# CC27x0 register map
File version: 1.0
CPU: CM4 r0p4, little endian, no MPU, no FPU, VTOR, 3 interrupt priority bits
Registers are 32-bit, read-write, reset 0x0 unless marked. A register's access mark holds for its fields unless they carry their own. Offsets are from the block's base; [hi:lo] are bit positions; {n}, {i} and the like mark numbered series; 'fields as' and 'values as' point back to an identical list.

## LRFDMDM32 (part 1 of 2)
Base 0x40082400
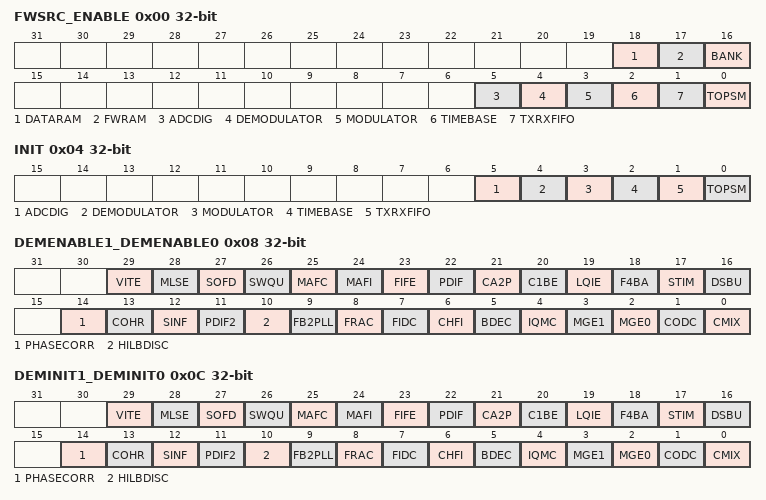
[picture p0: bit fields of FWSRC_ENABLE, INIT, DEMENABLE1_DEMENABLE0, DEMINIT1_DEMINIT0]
0x00 FWSRC_ENABLE — Internal. Only to be used through TI provided API.
  [18] DATARAM — Internal. Only to be used through TI provided API.
    1=S2RRAM (Internal. Only to be used through TI provided API.); 0=MDMRAM (Internal. Only to be used through TI provided API.)
  [17] FWRAM — Internal. Only to be used through TI provided API.
    values as DATARAM
  [16] BANK — Internal. Only to be used through TI provided API.
    1=ONE (Internal. Only to be used through TI provided API.); 0=ZERO (Internal. Only to be used through TI provided API.)
  [5] ADCDIG — Internal. Only to be used through TI provided API.
    1=EN (Internal. Only to be used through TI provided API.); 0=DIS (Internal. Only to be used through TI provided API.)
  [4] DEMODULATOR — Internal. Only to be used through TI provided API.
    values as ADCDIG
  [3] MODULATOR — Internal. Only to be used through TI provided API.
    values as ADCDIG
  [2] TIMEBASE — Internal. Only to be used through TI provided API.
    values as ADCDIG
  [1] TXRXFIFO — Internal. Only to be used through TI provided API.
    values as ADCDIG
  [0] TOPSM — Internal. Only to be used through TI provided API.
    values as ADCDIG
0x04 INIT wo — Internal. Only to be used through TI provided API.
  [all] fields
    1=RESET (Internal. Only to be used through TI provided API.); 0=NO_EFFECT (Internal. Only to be used through TI provided API.)
  [5] ADCDIG — Internal. Only to be used through TI provided API.
  [4] DEMODULATOR — Internal. Only to be used through TI provided API.
  [3] MODULATOR — Internal. Only to be used through TI provided API.
  [2] TIMEBASE — Internal. Only to be used through TI provided API.
  [1] TXRXFIFO — Internal. Only to be used through TI provided API.
  [0] TOPSM — Internal. Only to be used through TI provided API.
0x08 DEMENABLE1_DEMENABLE0 — Internal. Only to be used through TI provided API.
  [29] VITE — Internal. Only to be used through TI provided API.
    values as FWSRC_ENABLE.ADCDIG
  [28] MLSE — Internal. Only to be used through TI provided API.
    values as FWSRC_ENABLE.ADCDIG
  [27] SOFD — Internal. Only to be used through TI provided API.
    values as FWSRC_ENABLE.ADCDIG
  [26] SWQU — Internal. Only to be used through TI provided API.
    values as FWSRC_ENABLE.ADCDIG
  [25] MAFC — Internal. Only to be used through TI provided API.
    values as FWSRC_ENABLE.ADCDIG
  [24] MAFI — Internal. Only to be used through TI provided API.
    values as FWSRC_ENABLE.ADCDIG
  [23] FIFE — Internal. Only to be used through TI provided API.
    values as FWSRC_ENABLE.ADCDIG
  [22] PDIF — Internal. Only to be used through TI provided API.
    values as FWSRC_ENABLE.ADCDIG
  [21] CA2P — Internal. Only to be used through TI provided API.
    values as FWSRC_ENABLE.ADCDIG
  [20] C1BE — Internal. Only to be used through TI provided API.
    values as FWSRC_ENABLE.ADCDIG
  [19] LQIE — Internal. Only to be used through TI provided API.
    values as FWSRC_ENABLE.ADCDIG
  [18] F4BA — Internal. Only to be used through TI provided API.
    values as FWSRC_ENABLE.ADCDIG
  [17] STIM — Internal. Only to be used through TI provided API.
    values as FWSRC_ENABLE.ADCDIG
  [16] DSBU — Internal. Only to be used through TI provided API.
    values as FWSRC_ENABLE.ADCDIG
  [14] PHASECORR — Internal. Only to be used through TI provided API.
  [13] COHR — Internal. Only to be used through TI provided API.
  [12] SINF — Internal. Only to be used through TI provided API.
  [11] PDIF2 — Internal. Only to be used through TI provided API.
  [10] HILBDISC — Internal. Only to be used through TI provided API.
  [9] FB2PLL — Internal. Only to be used through TI provided API.
  [8] FRAC — Internal. Only to be used through TI provided API.
    values as FWSRC_ENABLE.ADCDIG
  [7] FIDC — Internal. Only to be used through TI provided API.
    values as FWSRC_ENABLE.ADCDIG
  [6] CHFI — Internal. Only to be used through TI provided API.
    values as FWSRC_ENABLE.ADCDIG
  [5] BDEC — Internal. Only to be used through TI provided API.
    values as FWSRC_ENABLE.ADCDIG
  [4] IQMC — Internal. Only to be used through TI provided API.
    values as FWSRC_ENABLE.ADCDIG
  [3] MGE1 — Internal. Only to be used through TI provided API.
    values as FWSRC_ENABLE.ADCDIG
  [2] MGE0 — Internal. Only to be used through TI provided API.
    values as FWSRC_ENABLE.ADCDIG
  [1] CODC — Internal. Only to be used through TI provided API.
    values as FWSRC_ENABLE.ADCDIG
  [0] CMIX — Internal. Only to be used through TI provided API.
    values as FWSRC_ENABLE.ADCDIG
0x0C DEMINIT1_DEMINIT0 wo — Internal. Only to be used through TI provided API.
  [29] VITE — Internal. Only to be used through TI provided API.
    values as the fields of INIT
  [28] MLSE — Internal. Only to be used through TI provided API.
    values as the fields of INIT
  [27] SOFD — Internal. Only to be used through TI provided API.
    values as the fields of INIT
  [26] SWQU — Internal. Only to be used through TI provided API.
    values as the fields of INIT
  [25] MAFC — Internal. Only to be used through TI provided API.
    values as the fields of INIT
  [24] MAFI — Internal. Only to be used through TI provided API.
    values as the fields of INIT
  [23] FIFE — Internal. Only to be used through TI provided API.
    values as the fields of INIT
  [22] PDIF — Internal. Only to be used through TI provided API.
    values as the fields of INIT
  [21] CA2P — Internal. Only to be used through TI provided API.
    values as the fields of INIT
  [20] C1BE — Internal. Only to be used through TI provided API.
    values as the fields of INIT
  [19] LQIE — Internal. Only to be used through TI provided API.
    values as the fields of INIT
  [18] F4BA — Internal. Only to be used through TI provided API.
    values as the fields of INIT
  [17] STIM — Internal. Only to be used through TI provided API.
    values as the fields of INIT
  [16] DSBU — Internal. Only to be used through TI provided API.
    values as the fields of INIT
  [14] PHASECORR — Internal. Only to be used through TI provided API.
  [13] COHR — Internal. Only to be used through TI provided API.
  [12] SINF — Internal. Only to be used through TI provided API.
  [11] PDIF2 — Internal. Only to be used through TI provided API.
  [10] HILBDISC — Internal. Only to be used through TI provided API.
  [9] FB2PLL — Internal. Only to be used through TI provided API.
  [8] FRAC — Internal. Only to be used through TI provided API.
    values as the fields of INIT
  [7] FIDC — Internal. Only to be used through TI provided API.
    values as the fields of INIT
  [6] CHFI — Internal. Only to be used through TI provided API.
    values as the fields of INIT
  [5] BDEC — Internal. Only to be used through TI provided API.
    values as the fields of INIT
  [4] IQMC — Internal. Only to be used through TI provided API.
    values as the fields of INIT
  [3] MGE1 — Internal. Only to be used through TI provided API.
    values as the fields of INIT
  [2] MGE0 — Internal. Only to be used through TI provided API.
    values as the fields of INIT
  [1] CODC — Internal. Only to be used through TI provided API.
    values as the fields of INIT
  [0] CMIX — Internal. Only to be used through TI provided API.
    values as the fields of INIT
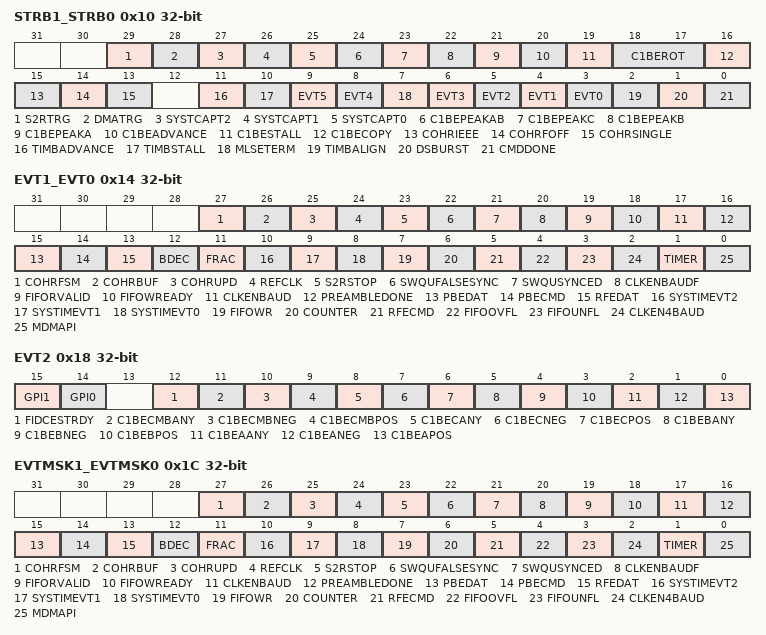
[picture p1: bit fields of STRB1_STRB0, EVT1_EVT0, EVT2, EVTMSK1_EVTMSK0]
0x10 STRB1_STRB0 wo — Internal. Only to be used through TI provided API.
  [29] S2RTRG — Internal. Only to be used through TI provided API.
    values as FWSRC_ENABLE.BANK
  [28] DMATRG — Internal. Only to be used through TI provided API.
    values as FWSRC_ENABLE.BANK
  [27] SYSTCAPT2 — Internal. Only to be used through TI provided API.
    values as FWSRC_ENABLE.BANK
  [26] SYSTCAPT1 — Internal. Only to be used through TI provided API.
    values as FWSRC_ENABLE.BANK
  [25] SYSTCAPT0 — Internal. Only to be used through TI provided API.
    values as FWSRC_ENABLE.BANK
  [24] C1BEPEAKAB — Internal. Only to be used through TI provided API.
    values as FWSRC_ENABLE.BANK
  [23] C1BEPEAKC — Internal. Only to be used through TI provided API.
    values as FWSRC_ENABLE.BANK
  [22] C1BEPEAKB — Internal. Only to be used through TI provided API.
    values as FWSRC_ENABLE.BANK
  [21] C1BEPEAKA — Internal. Only to be used through TI provided API.
    values as FWSRC_ENABLE.BANK
  [20] C1BEADVANCE — Internal. Only to be used through TI provided API.
    values as FWSRC_ENABLE.BANK
  [19] C1BESTALL — Internal. Only to be used through TI provided API.
    values as FWSRC_ENABLE.BANK
  [18:17] C1BEROT — Internal. Only to be used through TI provided API.
    3=ROT16R (Internal. Only to be used through TI provided API.); 2=ROT1L (Internal. Only to be used through TI provided API.); 1=ROT1R (Internal. Only to be used through TI provided API.); 0=ROT0 (Internal. Only to be used through TI provided API.)
  [16] C1BECOPY — Internal. Only to be used through TI provided API.
    values as FWSRC_ENABLE.BANK
  [15] COHRIEEE — Internal. Only to be used through TI provided API.
  [14] COHRFOFF — Internal. Only to be used through TI provided API.
  [13] COHRSINGLE — Internal. Only to be used through TI provided API.
  [11] TIMBADVANCE — Internal. Only to be used through TI provided API.
    1=ON (Internal. Only to be used through TI provided API.); 0=NO_EFFECT (Internal. Only to be used through TI provided API.)
  [10] TIMBSTALL — Internal. Only to be used through TI provided API.
    values as TIMBADVANCE
  [9] EVT5 — Internal. Only to be used through TI provided API.
    values as FWSRC_ENABLE.BANK
  [8] EVT4 — Internal. Only to be used through TI provided API.
    values as FWSRC_ENABLE.BANK
  [7] MLSETERM — Internal. Only to be used through TI provided API.
    1=ON (Internal. Only to be used through TI provided API.); 0=OFF (Internal. Only to be used through TI provided API.)
  [n+3] EVT{n} (n=0..3) — Internal. Only to be used through TI provided API.
    values as FWSRC_ENABLE.BANK
  [2] TIMBALIGN — Internal. Only to be used through TI provided API.
    values as TIMBADVANCE
  [1] DSBURST — Internal. Only to be used through TI provided API.
    1=RESTART (Internal. Only to be used through TI provided API.); 0=NO_EFFECT (Internal. Only to be used through TI provided API.)
  [0] CMDDONE — Internal. Only to be used through TI provided API.
    1=YES (Internal. Only to be used through TI provided API.); 0=NO (Internal. Only to be used through TI provided API.)
0x14 EVT1_EVT0 ro — Internal. Only to be used through TI provided API.
  [27] COHRFSM — Internal. Only to be used through TI provided API.
  [26] COHRBUF — Internal. Only to be used through TI provided API.
  [25] COHRUPD — Internal. Only to be used through TI provided API.
  [24] REFCLK — Internal. Only to be used through TI provided API.
    values as FWSRC_ENABLE.BANK
  [23] S2RSTOP — Internal. Only to be used through TI provided API.
    values as FWSRC_ENABLE.BANK
  [22] SWQUFALSESYNC — Internal. Only to be used through TI provided API.
    values as FWSRC_ENABLE.BANK
  [21] SWQUSYNCED — Internal. Only to be used through TI provided API.
    values as FWSRC_ENABLE.BANK
  [20] CLKENBAUDF — Internal. Only to be used through TI provided API.
    values as FWSRC_ENABLE.BANK
  [19] FIFORVALID — Internal. Only to be used through TI provided API.
    values as FWSRC_ENABLE.BANK
  [18] FIFOWREADY — Internal. Only to be used through TI provided API.
    values as FWSRC_ENABLE.BANK
  [17] CLKENBAUD — Internal. Only to be used through TI provided API.
    values as FWSRC_ENABLE.BANK
  [16] PREAMBLEDONE — Internal. Only to be used through TI provided API.
    values as FWSRC_ENABLE.BANK
  [15] PBEDAT — Internal. Only to be used through TI provided API.
    values as FWSRC_ENABLE.BANK
  [14] PBECMD — Internal. Only to be used through TI provided API.
    values as FWSRC_ENABLE.BANK
  [13] RFEDAT — Internal. Only to be used through TI provided API.
    values as FWSRC_ENABLE.BANK
  [12] BDEC — Internal. Only to be used through TI provided API.
    values as FWSRC_ENABLE.BANK
  [11] FRAC — Internal. Only to be used through TI provided API.
    values as FWSRC_ENABLE.BANK
  [10] SYSTIMEVT2 — Internal. Only to be used through TI provided API.
    values as FWSRC_ENABLE.BANK
  [9] SYSTIMEVT1 — Internal. Only to be used through TI provided API.
    values as FWSRC_ENABLE.BANK
  [8] SYSTIMEVT0 — Internal. Only to be used through TI provided API.
    values as FWSRC_ENABLE.BANK
  [7] FIFOWR — Internal. Only to be used through TI provided API.
    values as FWSRC_ENABLE.BANK
  [6] COUNTER — Internal. Only to be used through TI provided API.
    values as FWSRC_ENABLE.BANK
  [5] RFECMD — Internal. Only to be used through TI provided API.
    values as FWSRC_ENABLE.BANK
  [4] FIFOOVFL — Internal. Only to be used through TI provided API.
    values as FWSRC_ENABLE.BANK
  [3] FIFOUNFL — Internal. Only to be used through TI provided API.
    values as FWSRC_ENABLE.BANK
  [2] CLKEN4BAUD — Internal. Only to be used through TI provided API.
    values as FWSRC_ENABLE.BANK
  [1] TIMER — Internal. Only to be used through TI provided API.
    values as FWSRC_ENABLE.BANK
  [0] MDMAPI — Internal. Only to be used through TI provided API.
    values as FWSRC_ENABLE.BANK
0x18 EVT2 ro — Internal. Only to be used through TI provided API.
  [all] fields
    values as FWSRC_ENABLE.BANK
  [15] GPI1 — Internal. Only to be used through TI provided API.
  [14] GPI0 — Internal. Only to be used through TI provided API.
  [12] FIDCESTRDY — Internal. Only to be used through TI provided API.
  [11] C1BECMBANY — Internal. Only to be used through TI provided API.
  [10] C1BECMBNEG — Internal. Only to be used through TI provided API.
  [9] C1BECMBPOS — Internal. Only to be used through TI provided API.
  [8] C1BECANY — Internal. Only to be used through TI provided API.
  [7] C1BECNEG — Internal. Only to be used through TI provided API.
  [6] C1BECPOS — Internal. Only to be used through TI provided API.
  [5] C1BEBANY — Internal. Only to be used through TI provided API.
  [4] C1BEBNEG — Internal. Only to be used through TI provided API.
  [3] C1BEBPOS — Internal. Only to be used through TI provided API.
  [2] C1BEAANY — Internal. Only to be used through TI provided API.
  [1] C1BEANEG — Internal. Only to be used through TI provided API.
  [0] C1BEAPOS — Internal. Only to be used through TI provided API.
0x1C EVTMSK1_EVTMSK0 — Internal. Only to be used through TI provided API.
  [27] COHRFSM — Internal. Only to be used through TI provided API.
  [26] COHRBUF — Internal. Only to be used through TI provided API.
  [25] COHRUPD — Internal. Only to be used through TI provided API.
  [24] REFCLK — Internal. Only to be used through TI provided API.
    values as FWSRC_ENABLE.ADCDIG
  [23] S2RSTOP — Internal. Only to be used through TI provided API.
    values as FWSRC_ENABLE.ADCDIG
  [22] SWQUFALSESYNC — Internal. Only to be used through TI provided API.
    values as FWSRC_ENABLE.ADCDIG
  [21] SWQUSYNCED — Internal. Only to be used through TI provided API.
    values as FWSRC_ENABLE.ADCDIG
  [20] CLKENBAUDF — Internal. Only to be used through TI provided API.
    values as FWSRC_ENABLE.ADCDIG
  [19] FIFORVALID — Internal. Only to be used through TI provided API.
    values as FWSRC_ENABLE.ADCDIG
  [18] FIFOWREADY — Internal. Only to be used through TI provided API.
    values as FWSRC_ENABLE.ADCDIG
  [17] CLKENBAUD — Internal. Only to be used through TI provided API.
    values as FWSRC_ENABLE.ADCDIG
  [16] PREAMBLEDONE — Internal. Only to be used through TI provided API.
    values as FWSRC_ENABLE.ADCDIG
  [15] PBEDAT — Internal. Only to be used through TI provided API.
    values as FWSRC_ENABLE.ADCDIG
  [14] PBECMD — Internal. Only to be used through TI provided API.
    values as FWSRC_ENABLE.ADCDIG
  [13] RFEDAT — Internal. Only to be used through TI provided API.
    values as FWSRC_ENABLE.ADCDIG
  [12] BDEC — Internal. Only to be used through TI provided API.
    values as FWSRC_ENABLE.ADCDIG
  [11] FRAC — Internal. Only to be used through TI provided API.
    values as FWSRC_ENABLE.ADCDIG
  [10] SYSTIMEVT2 — Internal. Only to be used through TI provided API.
    values as FWSRC_ENABLE.ADCDIG
  [9] SYSTIMEVT1 — Internal. Only to be used through TI provided API.
    values as FWSRC_ENABLE.ADCDIG
  [8] SYSTIMEVT0 — Internal. Only to be used through TI provided API.
    values as FWSRC_ENABLE.ADCDIG
  [7] FIFOWR — Internal. Only to be used through TI provided API.
    values as FWSRC_ENABLE.ADCDIG
  [6] COUNTER — Internal. Only to be used through TI provided API.
    values as FWSRC_ENABLE.ADCDIG
  [5] RFECMD — Internal. Only to be used through TI provided API.
    values as FWSRC_ENABLE.ADCDIG
  [4] FIFOOVFL — Internal. Only to be used through TI provided API.
    values as FWSRC_ENABLE.ADCDIG
  [3] FIFOUNFL — Internal. Only to be used through TI provided API.
    values as FWSRC_ENABLE.ADCDIG
  [2] CLKEN4BAUD — Internal. Only to be used through TI provided API.
    values as FWSRC_ENABLE.ADCDIG
  [1] TIMER — Internal. Only to be used through TI provided API.
    values as FWSRC_ENABLE.ADCDIG
  [0] MDMAPI — Internal. Only to be used through TI provided API.
    values as FWSRC_ENABLE.ADCDIG
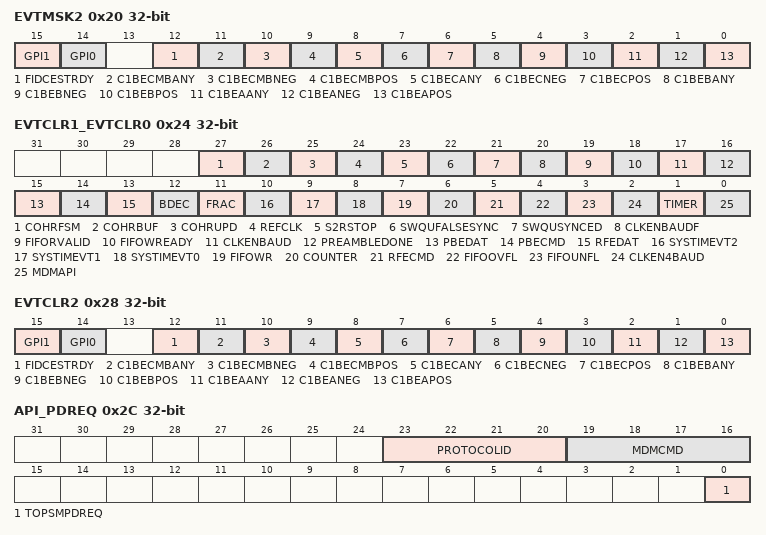
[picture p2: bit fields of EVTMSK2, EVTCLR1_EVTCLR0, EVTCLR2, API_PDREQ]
0x20 EVTMSK2 — Internal. Only to be used through TI provided API.
  [all] fields
    values as FWSRC_ENABLE.ADCDIG
  [15] GPI1 — Internal. Only to be used through TI provided API.
  [14] GPI0 — Internal. Only to be used through TI provided API.
  [12] FIDCESTRDY — Internal. Only to be used through TI provided API.
  [11] C1BECMBANY — Internal. Only to be used through TI provided API.
  [10] C1BECMBNEG — Internal. Only to be used through TI provided API.
  [9] C1BECMBPOS — Internal. Only to be used through TI provided API.
  [8] C1BECANY — Internal. Only to be used through TI provided API.
  [7] C1BECNEG — Internal. Only to be used through TI provided API.
  [6] C1BECPOS — Internal. Only to be used through TI provided API.
  [5] C1BEBANY — Internal. Only to be used through TI provided API.
  [4] C1BEBNEG — Internal. Only to be used through TI provided API.
  [3] C1BEBPOS — Internal. Only to be used through TI provided API.
  [2] C1BEAANY — Internal. Only to be used through TI provided API.
  [1] C1BEANEG — Internal. Only to be used through TI provided API.
  [0] C1BEAPOS — Internal. Only to be used through TI provided API.
0x24 EVTCLR1_EVTCLR0 wo — Internal. Only to be used through TI provided API.
  [27] COHRFSM — Internal. Only to be used through TI provided API.
  [26] COHRBUF — Internal. Only to be used through TI provided API.
  [25] COHRUPD — Internal. Only to be used through TI provided API.
  [24] REFCLK — Internal. Only to be used through TI provided API.
    1=CLEAR (Internal. Only to be used through TI provided API.); 0=RETAIN (Internal. Only to be used through TI provided API.)
  [23] S2RSTOP — Internal. Only to be used through TI provided API.
    values as REFCLK
  [22] SWQUFALSESYNC — Internal. Only to be used through TI provided API.
    values as REFCLK
  [21] SWQUSYNCED — Internal. Only to be used through TI provided API.
    values as REFCLK
  [20] CLKENBAUDF — Internal. Only to be used through TI provided API.
    values as REFCLK
  [19] FIFORVALID — Internal. Only to be used through TI provided API.
    values as REFCLK
  [18] FIFOWREADY — Internal. Only to be used through TI provided API.
    values as REFCLK
  [17] CLKENBAUD — Internal. Only to be used through TI provided API.
    values as REFCLK
  [16] PREAMBLEDONE — Internal. Only to be used through TI provided API.
    values as REFCLK
  [15] PBEDAT — Internal. Only to be used through TI provided API.
    values as REFCLK
  [14] PBECMD — Internal. Only to be used through TI provided API.
    values as REFCLK
  [13] RFEDAT — Internal. Only to be used through TI provided API.
    values as REFCLK
  [12] BDEC — Internal. Only to be used through TI provided API.
    values as REFCLK
  [11] FRAC — Internal. Only to be used through TI provided API.
    values as REFCLK
  [10] SYSTIMEVT2 — Internal. Only to be used through TI provided API.
    values as REFCLK
  [9] SYSTIMEVT1 — Internal. Only to be used through TI provided API.
    values as REFCLK
  [8] SYSTIMEVT0 — Internal. Only to be used through TI provided API.
    values as REFCLK
  [7] FIFOWR — Internal. Only to be used through TI provided API.
    values as REFCLK
  [6] COUNTER — Internal. Only to be used through TI provided API.
    values as REFCLK
  [5] RFECMD — Internal. Only to be used through TI provided API.
    values as REFCLK
  [4] FIFOOVFL — Internal. Only to be used through TI provided API.
    values as REFCLK
  [3] FIFOUNFL — Internal. Only to be used through TI provided API.
    values as REFCLK
  [2] CLKEN4BAUD — Internal. Only to be used through TI provided API.
    values as REFCLK
  [1] TIMER — Internal. Only to be used through TI provided API.
    values as REFCLK
  [0] MDMAPI — Internal. Only to be used through TI provided API.
    values as REFCLK
0x28 EVTCLR2 wo — Internal. Only to be used through TI provided API.
  [all] fields
    values as EVTCLR1_EVTCLR0.REFCLK
  [15] GPI1 — Internal. Only to be used through TI provided API.
  [14] GPI0 — Internal. Only to be used through TI provided API.
  [12] FIDCESTRDY — Internal. Only to be used through TI provided API.
  [11] C1BECMBANY — Internal. Only to be used through TI provided API.
  [10] C1BECMBNEG — Internal. Only to be used through TI provided API.
  [9] C1BECMBPOS — Internal. Only to be used through TI provided API.
  [8] C1BECANY — Internal. Only to be used through TI provided API.
  [7] C1BECNEG — Internal. Only to be used through TI provided API.
  [6] C1BECPOS — Internal. Only to be used through TI provided API.
  [5] C1BEBANY — Internal. Only to be used through TI provided API.
  [4] C1BEBNEG — Internal. Only to be used through TI provided API.
  [3] C1BEBPOS — Internal. Only to be used through TI provided API.
  [2] C1BEAANY — Internal. Only to be used through TI provided API.
  [1] C1BEANEG — Internal. Only to be used through TI provided API.
  [0] C1BEAPOS — Internal. Only to be used through TI provided API.
0x2C API_PDREQ — Internal. Only to be used through TI provided API.
  [23:20] PROTOCOLID ro — Internal. Only to be used through TI provided API.
    15=ALLONES (Internal. Only to be used through TI provided API.); 0=ALLZEROS (Internal. Only to be used through TI provided API.)
  [19:16] MDMCMD ro — Internal. Only to be used through TI provided API.
    values as PROTOCOLID
  [0] TOPSMPDREQ — Internal. Only to be used through TI provided API.
    values as STRB1_STRB0.MLSETERM
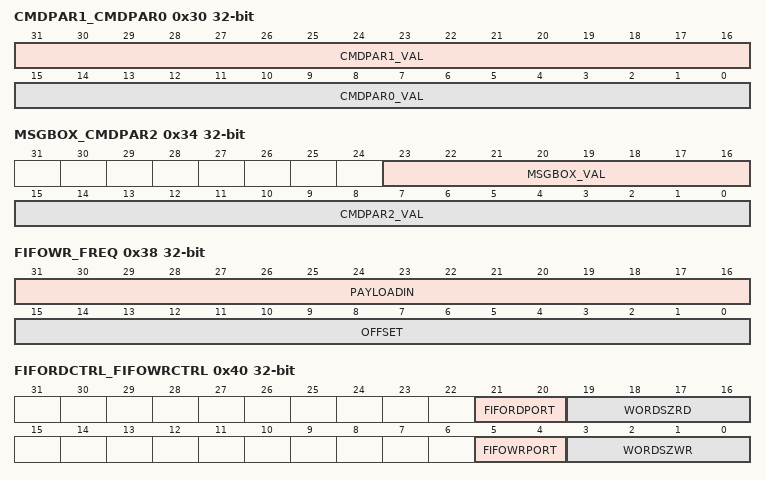
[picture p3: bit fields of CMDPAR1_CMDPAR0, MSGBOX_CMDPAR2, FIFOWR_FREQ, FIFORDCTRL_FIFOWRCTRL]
0x30 CMDPAR1_CMDPAR0 ro — Internal. Only to be used through TI provided API.
  [31:16] CMDPAR1_VAL — Internal. Only to be used through TI provided API.
    0xFFFF=ALLONES (Internal. Only to be used through TI provided API.); 0=ALLZEROS (Internal. Only to be used through TI provided API.)
  [15:0] CMDPAR0_VAL — Internal. Only to be used through TI provided API.
    values as CMDPAR1_VAL
0x34 MSGBOX_CMDPAR2 ro — Internal. Only to be used through TI provided API.
  [23:16] MSGBOX_VAL — Internal. Only to be used through TI provided API.
    255=ALLONES (Internal. Only to be used through TI provided API.); 0=ALLZEROS (Internal. Only to be used through TI provided API.)
  [15:0] CMDPAR2_VAL — Internal. Only to be used through TI provided API.
    values as CMDPAR1_CMDPAR0.CMDPAR1_VAL
0x38 FIFOWR_FREQ — Internal. Only to be used through TI provided API.
  [31:16] PAYLOADIN — Internal. Only to be used through TI provided API.
    values as CMDPAR1_CMDPAR0.CMDPAR1_VAL
  [15:0] OFFSET — Internal. Only to be used through TI provided API.
    values as CMDPAR1_CMDPAR0.CMDPAR1_VAL
0x3C FIFORD ro — Internal. Only to be used through TI provided API.
  [15:0] PAYLOADOUT
    values as CMDPAR1_CMDPAR0.CMDPAR1_VAL
0x40 FIFORDCTRL_FIFOWRCTRL — Internal. Only to be used through TI provided API.
  [21:20] FIFORDPORT — Internal. Only to be used through TI provided API.
    2=PBE (Internal. Only to be used through TI provided API.); 1=MODEM (Internal. Only to be used through TI provided API.); 0=MDMFIFORD (Internal. Only to be used through TI provided API.)
  [19:16] WORDSZRD — Internal. Only to be used through TI provided API.
    {v}=BITS{v+1} (Internal. Only to be used through TI provided API.) (v=0..15)
  [5:4] FIFOWRPORT — Internal. Only to be used through TI provided API.
    2=PBE (Internal. Only to be used through TI provided API.); 1=MODEM (Internal. Only to be used through TI provided API.); 0=MDMFIFOWR (Internal. Only to be used through TI provided API.)
  [3:0] WORDSZWR — Internal. Only to be used through TI provided API.
    values as WORDSZRD
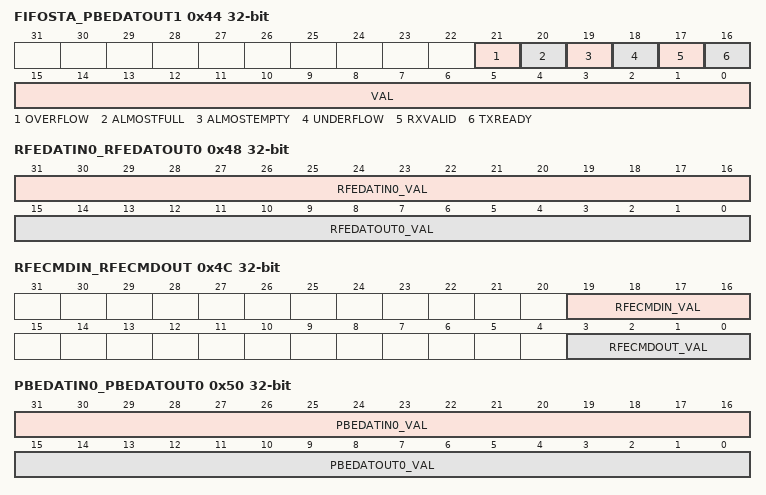
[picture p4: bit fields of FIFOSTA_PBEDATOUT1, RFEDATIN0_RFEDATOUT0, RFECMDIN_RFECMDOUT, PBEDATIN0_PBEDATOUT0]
0x44 FIFOSTA_PBEDATOUT1 — Internal. Only to be used through TI provided API.
  [21] OVERFLOW ro — Internal. Only to be used through TI provided API.
    values as FWSRC_ENABLE.BANK
  [20] ALMOSTFULL ro — Internal. Only to be used through TI provided API.
    values as FWSRC_ENABLE.BANK
  [19] ALMOSTEMPTY ro — Internal. Only to be used through TI provided API.
    values as FWSRC_ENABLE.BANK
  [18] UNDERFLOW ro — Internal. Only to be used through TI provided API.
    values as FWSRC_ENABLE.BANK
  [17] RXVALID ro — Internal. Only to be used through TI provided API.
    values as FWSRC_ENABLE.BANK
  [16] TXREADY ro — Internal. Only to be used through TI provided API.
    values as FWSRC_ENABLE.BANK
  [15:0] VAL — Internal. Only to be used through TI provided API.
    values as CMDPAR1_CMDPAR0.CMDPAR1_VAL
0x48 RFEDATIN0_RFEDATOUT0 — Internal. Only to be used through TI provided API.
  [31:16] RFEDATIN0_VAL ro — Internal. Only to be used through TI provided API.
    values as CMDPAR1_CMDPAR0.CMDPAR1_VAL
  [15:0] RFEDATOUT0_VAL — Internal. Only to be used through TI provided API.
    values as CMDPAR1_CMDPAR0.CMDPAR1_VAL
0x4C RFECMDIN_RFECMDOUT — Internal. Only to be used through TI provided API.
  [19:16] RFECMDIN_VAL ro — Internal. Only to be used through TI provided API.
    values as API_PDREQ.PROTOCOLID
  [3:0] RFECMDOUT_VAL — Internal. Only to be used through TI provided API.
    values as API_PDREQ.PROTOCOLID
0x50 PBEDATIN0_PBEDATOUT0 — Internal. Only to be used through TI provided API.
  [31:16] PBEDATIN0_VAL ro — Internal. Only to be used through TI provided API.
    values as CMDPAR1_CMDPAR0.CMDPAR1_VAL
  [15:0] PBEDATOUT0_VAL — Internal. Only to be used through TI provided API.
    values as CMDPAR1_CMDPAR0.CMDPAR1_VAL
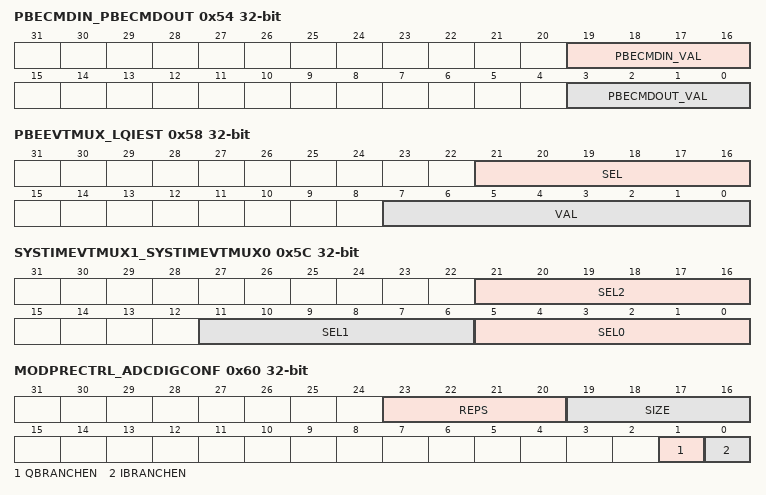
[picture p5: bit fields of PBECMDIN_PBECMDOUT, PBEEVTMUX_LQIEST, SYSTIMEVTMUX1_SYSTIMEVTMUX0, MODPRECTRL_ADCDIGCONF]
0x54 PBECMDIN_PBECMDOUT — Internal. Only to be used through TI provided API.
  [19:16] PBECMDIN_VAL ro — Internal. Only to be used through TI provided API.
    values as API_PDREQ.PROTOCOLID
  [3:0] PBECMDOUT_VAL — Internal. Only to be used through TI provided API.
    values as API_PDREQ.PROTOCOLID
0x58 PBEEVTMUX_LQIEST — Internal. Only to be used through TI provided API.
  [21:16] SEL — Internal. Only to be used through TI provided API.
    63=ALLONES (Internal. Only to be used through TI provided API.); 0=ALLZEROS (Internal. Only to be used through TI provided API.)
  [7:0] VAL — Internal. Only to be used through TI provided API.
    values as MSGBOX_CMDPAR2.MSGBOX_VAL
0x5C SYSTIMEVTMUX1_SYSTIMEVTMUX0 — Internal. Only to be used through TI provided API.
  [all] fields
    values as PBEEVTMUX_LQIEST.SEL
  [21:16] SEL2 — Internal. Only to be used through TI provided API.
  [11:6] SEL1 — Internal. Only to be used through TI provided API.
  [5:0] SEL0 — Internal. Only to be used through TI provided API.
0x60 MODPRECTRL_ADCDIGCONF — Internal. Only to be used through TI provided API.
  [23:20] REPS — Internal. Only to be used through TI provided API.
    {v}=Internal. Only to be used through TI provided API. (v=0..15)
  [19:16] SIZE — Internal. Only to be used through TI provided API.
    15=BITS16 (Internal. Only to be used through TI provided API.); 7=BITS8 (Internal. Only to be used through TI provided API.); 3=BITS4 (Internal. Only to be used through TI provided API.)
  [1] QBRANCHEN — Internal. Only to be used through TI provided API.
    values as STRB1_STRB0.MLSETERM
  [0] IBRANCHEN — Internal. Only to be used through TI provided API.
    values as STRB1_STRB0.MLSETERM
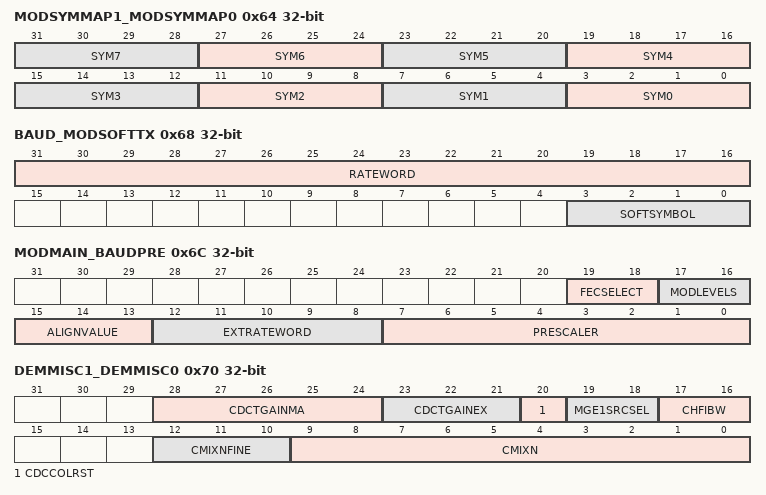
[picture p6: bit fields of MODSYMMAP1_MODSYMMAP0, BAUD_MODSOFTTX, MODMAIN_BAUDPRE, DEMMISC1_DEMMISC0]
0x64 MODSYMMAP1_MODSYMMAP0 — Internal. Only to be used through TI provided API.
  [all] fields
    values as API_PDREQ.PROTOCOLID
  [4n+3:4n] SYM{n} (n=0..7) — Internal. Only to be used through TI provided API.
0x68 BAUD_MODSOFTTX — Internal. Only to be used through TI provided API.
  [31:16] RATEWORD — Internal. Only to be used through TI provided API.
    values as CMDPAR1_CMDPAR0.CMDPAR1_VAL
  [3:0] SOFTSYMBOL — Internal. Only to be used through TI provided API.
    values as API_PDREQ.PROTOCOLID
0x6C MODMAIN_BAUDPRE — Internal. Only to be used through TI provided API.
  [19:18] FECSELECT — Internal. Only to be used through TI provided API.
    3=BLR (Internal. Only to be used through TI provided API.); 2=RESERVED (Internal. Only to be used through TI provided API.); 1=IEEE15_4 (Internal. Only to be used through TI provided API.); 0=NOSEL (Internal. Only to be used through TI provided API.)
  [17:16] MODLEVELS — Internal. Only to be used through TI provided API.
    2=LVL8 (Internal. Only to be used through TI provided API.); 1=LVL4 (Internal. Only to be used through TI provided API.); 0=LVL2 (Internal. Only to be used through TI provided API.)
  [15:13] ALIGNVALUE — Internal. Only to be used through TI provided API.
    7=ALLONES (Internal. Only to be used through TI provided API.); 0=ALLZEROS (Internal. Only to be used through TI provided API.)
  [12:8] EXTRATEWORD — Internal. Only to be used through TI provided API.
    31=ALLONES (Internal. Only to be used through TI provided API.); 0=ALLZEROS (Internal. Only to be used through TI provided API.)
  [7:0] PRESCALER — Internal. Only to be used through TI provided API.
    values as MSGBOX_CMDPAR2.MSGBOX_VAL
0x70 DEMMISC1_DEMMISC0 — Internal. Only to be used through TI provided API.
  [28:24] CDCTGAINMA — Internal. Only to be used through TI provided API.
    values as MODMAIN_BAUDPRE.EXTRATEWORD
  [23:21] CDCTGAINEX — Internal. Only to be used through TI provided API.
    values as MODMAIN_BAUDPRE.ALIGNVALUE
  [20] CDCCOLRST — Internal. Only to be used through TI provided API.
    values as FWSRC_ENABLE.ADCDIG
  [19:18] MGE1SRCSEL — Internal. Only to be used through TI provided API.
    2=CHFI (Internal. Only to be used through TI provided API.); 1=FEXB1 (Internal. Only to be used through TI provided API.); 0=FIDC (Internal. Only to be used through TI provided API.)
  [17:16] CHFIBW — Internal. Only to be used through TI provided API.
    3=BW0_29 (Internal. Only to be used through TI provided API.); 2=BW0_41667 (Internal. Only to be used through TI provided API.); 1=BW0_3333 (Internal. Only to be used through TI provided API.); 0=BW0_5 (Internal. Only to be used through TI provided API.)
  [12:10] CMIXNFINE — Internal. Only to be used through TI provided API.
  [9:0] CMIXN — Internal. Only to be used through TI provided API.
    0x3FF=ALLONES (Internal. Only to be used through TI provided API.); 0=ALLZEROS (Internal. Only to be used through TI provided API.)
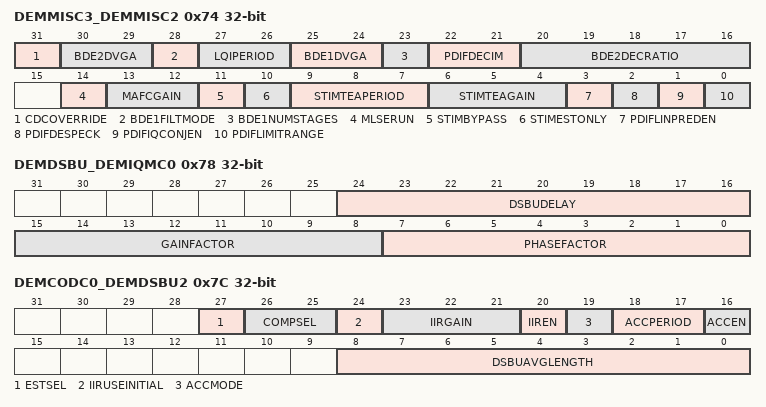
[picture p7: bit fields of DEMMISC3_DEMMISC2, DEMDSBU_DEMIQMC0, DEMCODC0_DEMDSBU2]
0x74 DEMMISC3_DEMMISC2 — Internal. Only to be used through TI provided API.
  [31] CDCOVERRIDE — Internal. Only to be used through TI provided API.
    3=GAIN8 (Internal. Only to be used through TI provided API.); 2=GAIN4 (Internal. Only to be used through TI provided API.); 1=GAIN2 (Internal. Only to be used through TI provided API.); 0=GAIN1 (Internal. Only to be used through TI provided API.)
  [30:29] BDE2DVGA — Internal. Only to be used through TI provided API.
    values as CDCOVERRIDE
  [28] BDE1FILTMODE — Internal. Only to be used through TI provided API.
    1=DIV2 (Internal. Only to be used through TI provided API.); 0=DIV1 (Internal. Only to be used through TI provided API.)
  [27:26] LQIPERIOD — Internal. Only to be used through TI provided API.
    3=SYM1024 (Internal. Only to be used through TI provided API.); 2=SYM256 (Internal. Only to be used through TI provided API.); 1=SYM64 (Internal. Only to be used through TI provided API.); 0=SYM16 (Internal. Only to be used through TI provided API.)
  [25:24] BDE1DVGA — Internal. Only to be used through TI provided API.
    values as CDCOVERRIDE
  [23] BDE1NUMSTAGES — Internal. Only to be used through TI provided API.
    values as BDE1FILTMODE
  [22:21] PDIFDECIM — Internal. Only to be used through TI provided API.
    2=DIV4 (Internal. Only to be used through TI provided API.); 1=DIV2 (Internal. Only to be used through TI provided API.); 0=DIV1 (Internal. Only to be used through TI provided API.)
  [20:16] BDE2DECRATIO — Internal. Only to be used through TI provided API.
    3=DIV8 (Internal. Only to be used through TI provided API.); 2=DIV4 (Internal. Only to be used through TI provided API.); 1=DIV2 (Internal. Only to be used through TI provided API.); 0=DIV1 (Internal. Only to be used through TI provided API.)
  [14] MLSERUN — Internal. Only to be used through TI provided API.
    values as FWSRC_ENABLE.ADCDIG
  [13:12] MAFCGAIN — Internal. Only to be used through TI provided API.
    3=ALLONES (Internal. Only to be used through TI provided API.); 0=ALLZEROS (Internal. Only to be used through TI provided API.)
  [11] STIMBYPASS — Internal. Only to be used through TI provided API.
    values as FWSRC_ENABLE.ADCDIG
  [10] STIMESTONLY — Internal. Only to be used through TI provided API.
    values as FWSRC_ENABLE.ADCDIG
  [9:7] STIMTEAPERIOD — Internal. Only to be used through TI provided API.
    5=SYM128 (Internal. Only to be used through TI provided API.); 4=SYM64 (Internal. Only to be used through TI provided API.); 3=SYM32 (Internal. Only to be used through TI provided API.); 2=SYM16 (Internal. Only to be used through TI provided API.); 1=SYM8 (Internal. Only to be used through TI provided API.); 0=SYM4 (Internal. Only to be used through TI provided API.)
  [6:4] STIMTEAGAIN — Internal. Only to be used through TI provided API.
    7=DIV4 (Internal. Only to be used through TI provided API.); 6=DIV8 (Internal. Only to be used through TI provided API.); 5=DIV16 (Internal. Only to be used through TI provided API.); 4=DIV32 (Internal. Only to be used through TI provided API.); 3=DIV64 (Internal. Only to be used through TI provided API.); 2=DIV128 (Internal. Only to be used through TI provided API.); 1=DIV256 (Internal. Only to be used through TI provided API.); 0=DIV512 (Internal. Only to be used through TI provided API.)
  [3] PDIFLINPREDEN — Internal. Only to be used through TI provided API.
    values as STRB1_STRB0.MLSETERM
  [2] PDIFDESPECK — Internal. Only to be used through TI provided API.
    values as FWSRC_ENABLE.ADCDIG
  [1] PDIFIQCONJEN — Internal. Only to be used through TI provided API.
    values as STRB1_STRB0.MLSETERM
  [0] PDIFLIMITRANGE — Internal. Only to be used through TI provided API.
    values as FWSRC_ENABLE.ADCDIG
0x78 DEMDSBU_DEMIQMC0 — Internal. Only to be used through TI provided API.
  [all] fields
    values as MSGBOX_CMDPAR2.MSGBOX_VAL
  [24:16] DSBUDELAY — Internal. Only to be used through TI provided API.
  [15:8] GAINFACTOR — Internal. Only to be used through TI provided API.
  [7:0] PHASEFACTOR — Internal. Only to be used through TI provided API.
0x7C DEMCODC0_DEMDSBU2 — Internal. Only to be used through TI provided API.
  [27] ESTSEL — Internal. Only to be used through TI provided API.
    1=IIR (Internal. Only to be used through TI provided API.); 0=ACC (Internal. Only to be used through TI provided API.)
  [26:25] COMPSEL — Internal. Only to be used through TI provided API.
    3=IIR (Internal. Only to be used through TI provided API.); 2=ACC (Internal. Only to be used through TI provided API.); 0=MANUAL (Internal. Only to be used through TI provided API.)
  [24] IIRUSEINITIAL — Internal. Only to be used through TI provided API.
    values as FWSRC_ENABLE.ADCDIG
  [23:21] IIRGAIN — Internal. Only to be used through TI provided API.
    7=DIV1024 (Internal. Only to be used through TI provided API.); 6=DIV512 (Internal. Only to be used through TI provided API.); 5=DIV256 (Internal. Only to be used through TI provided API.); 4=DIV128 (Internal. Only to be used through TI provided API.); 3=DIV64 (Internal. Only to be used through TI provided API.); 2=DIV32 (Internal. Only to be used through TI provided API.); 1=DIV16 (Internal. Only to be used through TI provided API.); 0=OFF (Internal. Only to be used through TI provided API.)
  [20] IIREN — Internal. Only to be used through TI provided API.
    values as STRB1_STRB0.MLSETERM
  [19] ACCMODE — Internal. Only to be used through TI provided API.
    1=CONT (Internal. Only to be used through TI provided API.); 0=SINGLE (Internal. Only to be used through TI provided API.)
  [18:17] ACCPERIOD — Internal. Only to be used through TI provided API.
    3=SMPL512 (Internal. Only to be used through TI provided API.); 2=SMPL128 (Internal. Only to be used through TI provided API.); 1=SMPL32 (Internal. Only to be used through TI provided API.); 0=SMPL8 (Internal. Only to be used through TI provided API.)
  [16] ACCEN — Internal. Only to be used through TI provided API.
    values as STRB1_STRB0.MLSETERM
  [8:0] DSBUAVGLENGTH — Internal. Only to be used through TI provided API.
